# ATSAMA5D27 register map
Vendor: Microchip Technology Inc.; File version: 1.0
CPU: CA5 r0p1, little endian, no MPU, no FPU, 4 interrupt priority bits
Address unit: 32 bits
Registers are 32-bit, read-write, reset 0x0 unless marked. A register's access mark holds for its fields unless they carry their own. Offsets are from the block's base; [hi:lo] are bit positions.

## ICM — Integrity Check Monitor
Base 0xF8040000
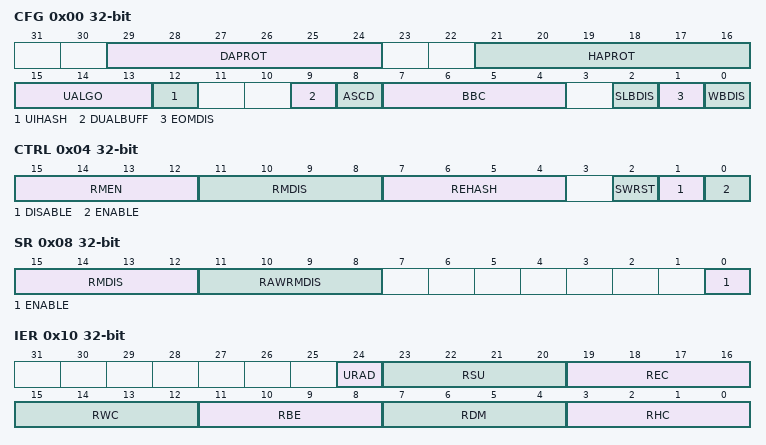
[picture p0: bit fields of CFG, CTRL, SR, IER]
0x00 CFG — Configuration Register
  [29:24] DAPROT — Region Descriptor Area Protection
  [21:16] HAPROT — Region Hash Area Protection
  [15:13] UALGO — User SHA Algorithm
    0=SHA1 (SHA1 algorithm processed); 1=SHA256 (SHA256 algorithm processed); 4=SHA224 (SHA224 algorithm processed)
  [12] UIHASH — User Initial Hash Value
  [9] DUALBUFF — Dual Input Buffer
  [8] ASCD — Automatic Switch To Compare Digest
  [7:4] BBC — Bus Burden Control
  [2] SLBDIS — Secondary List Branching Disable
  [1] EOMDIS — End of Monitoring Disable
  [0] WBDIS — Write Back Disable
0x04 CTRL wo — Control Register
  [15:12] RMEN rw — Region Monitoring Enable
  [11:8] RMDIS rw — Region Monitoring Disable
  [7:4] REHASH rw — Recompute Internal Hash
  [2] SWRST rw — Software Reset
  [1] DISABLE rw — ICM Disable Register
  [0] ENABLE rw — ICM Enable
0x08 SR ro — Status Register
  [15:12] RMDIS rw — Region Monitoring Disabled Status
  [11:8] RAWRMDIS rw — Region Monitoring Disabled Raw Status
  [0] ENABLE rw — ICM Enable Register
0x10 IER wo — Interrupt Enable Register
  [24] URAD rw — Undefined Register Access Detection Interrupt Enable
  [23:20] RSU rw — Region Status Updated Interrupt Disable
  [19:16] REC rw — Region End bit Condition Detected Interrupt Enable
  [15:12] RWC rw — Region Wrap Condition detected Interrupt Enable
  [11:8] RBE rw — Region Bus Error Interrupt Enable
  [7:4] RDM rw — Region Digest Mismatch Interrupt Enable
  [3:0] RHC rw — Region Hash Completed Interrupt Enable
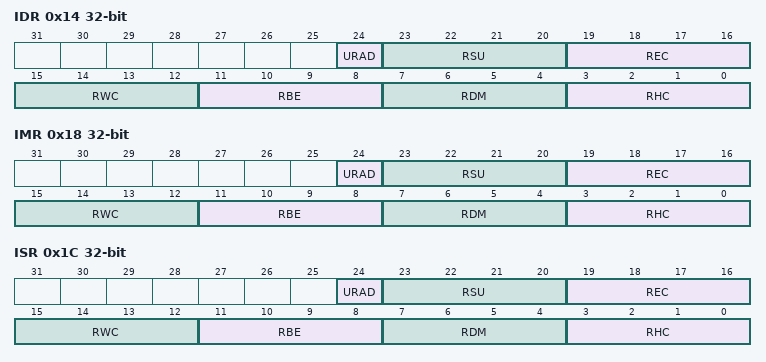
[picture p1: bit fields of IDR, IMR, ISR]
0x14 IDR wo — Interrupt Disable Register
  [24] URAD rw — Undefined Register Access Detection Interrupt Disable
  [23:20] RSU rw — Region Status Updated Interrupt Disable
  [19:16] REC rw — Region End bit Condition detected Interrupt Disable
  [15:12] RWC rw — Region Wrap Condition Detected Interrupt Disable
  [11:8] RBE rw — Region Bus Error Interrupt Disable
  [7:4] RDM rw — Region Digest Mismatch Interrupt Disable
  [3:0] RHC rw — Region Hash Completed Interrupt Disable
0x18 IMR ro — Interrupt Mask Register
  [24] URAD rw — Undefined Register Access Detection Interrupt Mask
  [23:20] RSU rw — Region Status Updated Interrupt Mask
  [19:16] REC rw — Region End bit Condition Detected Interrupt Mask
  [15:12] RWC rw — Region Wrap Condition Detected Interrupt Mask
  [11:8] RBE rw — Region Bus Error Interrupt Mask
  [7:4] RDM rw — Region Digest Mismatch Interrupt Mask
  [3:0] RHC rw — Region Hash Completed Interrupt Mask
0x1C ISR ro — Interrupt Status Register
  [24] URAD rw — Undefined Register Access Detection Status
  [23:20] RSU rw — Region Status Updated Detected
  [19:16] REC rw — Region End Bit Condition Detected
  [15:12] RWC rw — Region Wrap Condition Detected
  [11:8] RBE rw — Region Bus Error
  [7:4] RDM rw — Region Digest Mismatch
  [3:0] RHC rw — Region Hash Completed
0x20 UASR ro — Undefined Access Status Register
  [2:0] URAT rw — Undefined Register Access Trace
    0=UNSPEC_STRUCT_MEMBER (Unspecified structure member set to one detected when the descriptor is loaded.); 1=ICM_CFG_MODIFIED (ICM_CFG modified during active monitoring.); 2=ICM_DSCR_MODIFIED (ICM_DSCR modified during active monitoring.); 3=ICM_HASH_MODIFIED (ICM_HASH modified during active monitoring); 4=READ_ACCESS (Write-only register read access)
0x30 DSCR — Region Descriptor Area Start Address Register
  [31:6] DASA — Descriptor Area Start Address
0x34 HASH — Region Hash Area Start Address Register
  [31:7] HASA — Hash Area Start Address
0x38 UIHVAL wo — User Initial Hash Value 0 Register
  [31:0] VAL rw — Initial Hash Value

## PDMIC — Pulse Density Modulation Interface Controller
Base 0xF8018000
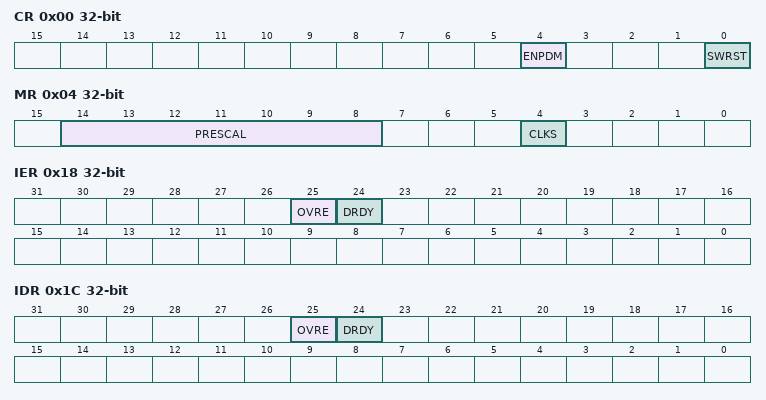
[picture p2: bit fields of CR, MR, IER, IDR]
0x00 CR — Control Register
  [4] ENPDM — Enable PDM
  [0] SWRST — Software Reset
0x04 MR — Mode Register
  [14:8] PRESCAL — Prescaler Rate Selection
  [4] CLKS — Clock Source Selection
0x14 CDR ro — Converted Data Register
  [31:0] DATA rw — Data Converted
0x18 IER wo — Interrupt Enable Register
  [25] OVRE rw — Overrun Error Interrupt Enable
  [24] DRDY rw — Data Ready Interrupt Enable
0x1C IDR wo — Interrupt Disable Register
  [25] OVRE rw — General Overrun Error Interrupt Disable
  [24] DRDY rw — Data Ready Interrupt Disable
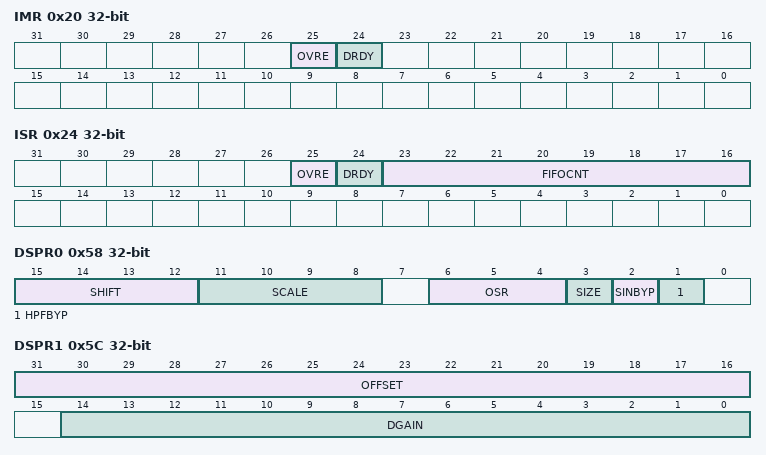
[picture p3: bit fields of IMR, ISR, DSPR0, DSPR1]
0x20 IMR ro — Interrupt Mask Register
  [25] OVRE rw — General Overrun Error Interrupt Mask
  [24] DRDY rw — Data Ready Interrupt Mask
0x24 ISR ro — Interrupt Status Register
  [25] OVRE rw — Overrun Error (cleared on read)
  [24] DRDY rw — Data Ready (cleared by reading PDMIC_CDR)
  [23:16] FIFOCNT rw — FIFO Count
0x58 DSPR0 — DSP Configuration Register 0
  [15:12] SHIFT — Data Shift
  [11:8] SCALE — Data Scale
  [6:4] OSR — Global Oversampling Ratio
    0=Global Oversampling ratio is 128 (SINC filter oversampling ratio is 64); 1=Global Oversampling ratio is 64 (SINC filter oversampling ratio is 32)
  [3] SIZE — Data Size
  [2] SINBYP — SINCC Filter Bypass
  [1] HPFBYP — High-Pass Filter Bypass
0x5C DSPR1 — DSP Configuration Register 1
  [31:16] OFFSET — Offset Correction
  [14:0] DGAIN — Gain Correction
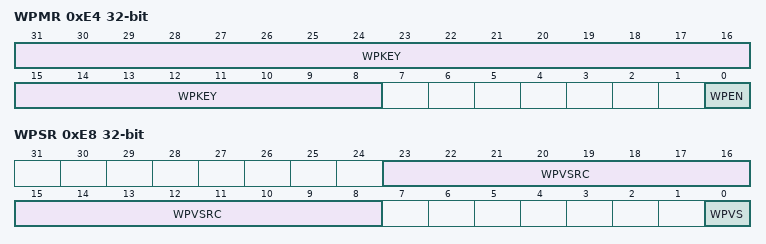
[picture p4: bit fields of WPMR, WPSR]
0xE4 WPMR — Write Protection Mode Register
  [31:8] WPKEY — Write Protection Key
    0x414443=PASSWD (Writing any other value in this field aborts the write operation of the WPEN bit.Always reads as 0.)
  [0] WPEN — Write Protection Enable
0xE8 WPSR ro — Write Protection Status Register
  [23:8] WPVSRC rw — Write Protection Violation Source
  [0] WPVS rw — Write Protection Violation Status
